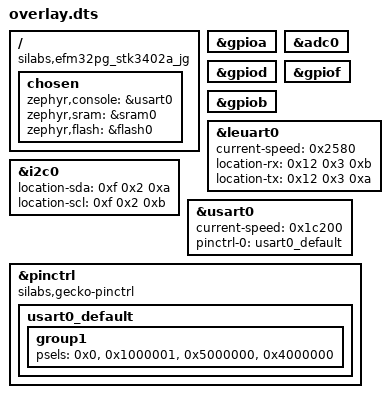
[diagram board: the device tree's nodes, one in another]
/ {
	compatible = "silabs,efm32pg_stk3402a_jg", "silabs,efm32jg12b";
	chosen {
		zephyr,console = &usart0;
		zephyr,sram = &sram0;
		zephyr,flash = &flash0;
	};
};
&gpioa{
	status = "okay";
};
&adc0{
	status = "okay";
};
&gpiod{
	status = "okay";
};
&gpiof{
	status = "okay";
};
&gpiob{
	status = "okay";
};
&leuart0{
	status = "okay";
	current-speed = < 0x2580 >;
	location-rx = < 0x12 0x3 0xb >;
	location-tx = < 0x12 0x3 0xa >;
};
&i2c0{
	status = "okay";
	location-sda = < 0xf 0x2 0xa >;
	location-scl = < 0xf 0x2 0xb >;
};
&usart0{
	status = "okay";
	current-speed = < 0x1c200 >;
	pinctrl-0 = < &usart0_default >;
	pinctrl-names = "default";
};
&pinctrl{
	compatible = "silabs,gecko-pinctrl";
	usart0_default: usart0_default {
		group1 {
			psels = < 0x0 >, < 0x1000001 >, < 0x5000000 >, < 0x4000000 >;
		};
	};
};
